# IPE3_LSE_ICONT register map
Vendor: Texas Instruments
Peripheral module from a debugger description file (folder TDA2Px).
Registers are 32-bit, access not given, reset 0x1 unless marked. A register's access mark holds for its fields unless they carry their own. Offsets are as the file gives them; lines under a group give offsets from that group; [hi:lo] are bit positions; {n}, {i} and the like mark numbered series; 'fields as' and 'values as' point back to an identical list; <NAME> marks a mode.

## IPE3_LSE_ICONT
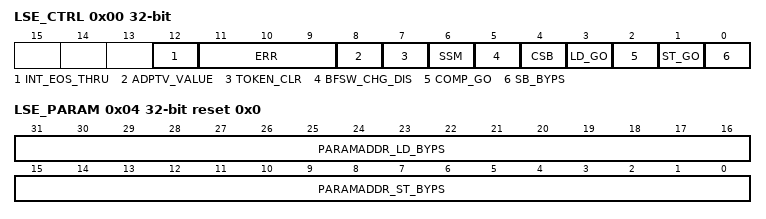
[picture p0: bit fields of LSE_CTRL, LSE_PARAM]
0x00 LSE_CTRL — Controller
  [12] INT_EOS_THRU rw — int_eos through bit 0: LSE processes for the slice boundary after receiving int_eos. 1: int_eos is passed through to SYNCBOX_IPE3 without the process for the slice boundary.
  [11:9] ERR — Error status bit [11]: DMA IP_CORE side [10]: DMA SL2 side [9]: CFG IP_CORE side 0: Sresp is not ERR. 1: Sresp is ERR. Writing 0 is ignored. These bits remain 1 until reset or until the host sets to 1. (access RW WSpecial)
  [8] ADPTV_VALUE ro — Status Adaptv_add() value. This signal is cleared if Token_clr = 1.
  [7] TOKEN_CLR — LSE internal signals are initialized to recognize the prologue (first MB): -Token status signal -Token start/end signal -DMA pointer Writing 0 is ignored. Writing 1 clears some internal signals. This is a self-clearing bit. The host always reads 0. If this is not used for initialization at prologue, some internal signals are kept. Synchronization does not function well. (access W WSpecial)
  [6] SSM rw — Single-step mode 1: Enable Single-step mode 0: Normal mode
  [5] BFSW_CHG_DIS rw — Disabled internal BFSW change 0: Enable internal BFSW change (default) Then, LSE controls BFSW after LD task completes. 1: Disable BFSW change (for host to control BFSW with each task step by step with LD_GO, Comp_GO and ST_GO).
  [4] CSB — Command status bit 0: LSE command is defined. 1: LSE command is undefined. Writing 0 is ignored . These bits remain 1 until reset or Token_clr or until host sets to 1. (access RW WSpecial)
  [3] LD_GO — Execute LOAD task in bypass mode. Target ParamAddr_ld_byps must be set before this bit is set. 1: Execute LD task. LSE accesses ParamAddr_ld_byps and executes the command for the LOAD task. 0: Idle Writing 0 is ignored. This bit is cleared after the LD task completes. (access RW WSpecial)
  [2] COMP_GO — Execute Comp task in bypass mode. 1: Execute Comp task. In single-step mode, LSE accesses ParamAddr_ld_byps and executes the command for the Comp task. In normal mode, LSE executes COMP commands followed by LD commands. 0: Idle Writing 0 is ignored. This bit is cleared after the Comp task completes. (access RW WSpecial)
  [1] ST_GO — Execute Store task in bypass mode. Target ParamAddr_st_byps must be set before this bit is set. 1: Execute Store task. LSE accesses ParamAddr_st_byps and executes the command for the Store task. 0: Idle Writing 0 is ignored. This bit is cleared after the ST task completes. (access RW WSpecial)
  [0] SB_BYPS rw — Sync-Box bypass mode 1: LSE functions in SYNCBOX_IPE3 bypass mode and executes the task of the go_bit. 0: LSE functions in normal SYNCBOX_IPE3 mode and waits for NewTaskSignal. This value must not change during execution.
0x04 LSE_PARAM rw reset 0x0 — Parameter address for SB bypass mode
  [31:16] PARAMADDR_LD_BYPS — Bypass mode only. Address of the first command of LD and COMP sequence (128-bit word unit). This is a 128-bit word address, not a byte address. The conversion from byte address to 128-bit word address must be done by CPU. IfLSE_CTRL SB_BYPS is 1, this value is used. In bypass mode, this address is given in this field, instead of through SYNCBOX_IPE3 And also, this field will be used in single-step mode.
  [15:0] PARAMADDR_ST_BYPS — Bypass mode only. Address of the first command of ST sequence (128-bit word unit). This is a 128-bit word address, not a byte address. The byte address is converted to a 128-bit word address by the CPU. IfLSE_CTRL SB_BYPS is 1, this value is used. In bypass mode, this address is given in this field, instead of through SYNCBOX_IPE3. This field is also used in single-step mode.
